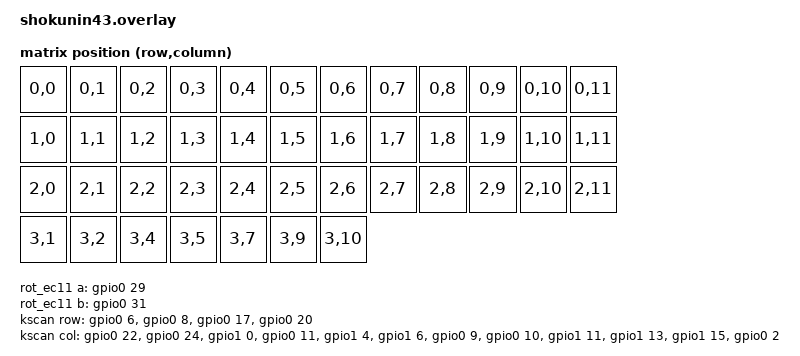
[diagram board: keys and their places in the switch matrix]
// This file was generated from a template. Edit it to match your keyboard.
// See https://zmk.dev/docs/development/hardware-integration/new-shield for more
// instructions.

#include <dt-bindings/zmk/matrix_transform.h>

#include "shokunin43-layouts.dtsi"

/ {
    chosen {
        zmk,physical-layout = &default_layout;
    };

	rot_ec11: encoder {
		compatible = "alps,ec11";
        a-gpios = <&gpio0 29 (GPIO_ACTIVE_HIGH | GPIO_PULL_UP)>;
        b-gpios = <&gpio0 31 (GPIO_ACTIVE_HIGH | GPIO_PULL_UP)>;
        steps = <80>;
	};

    sensors: sensors {
        compatible = "zmk,keymap-sensors";
        sensors = <&rot_ec11>;
        triggers-per-rotation = <20>;
        left {
            triggers-per-rotation = <20>;
        };
    };	

    kscan: kscan {
        // If the hardware does not use a switch matrix, change this to the
        // appropriate driver and update the properties below to match.
        // See https://zmk.dev/docs/config/kscan for supported key scan drivers.
        compatible = "zmk,kscan-gpio-matrix";
        // Set this to "col2row" or "row2col" to match the hardware. If using
        // "row2col", change the col-gpios to (GPIO_ACTIVE_HIGH | GPIO_PULL_DOWN)
        // and the row-gpios to GPIO_ACTIVE_HIGH.
        diode-direction = "col2row";
        wakeup-source;

        // Replace these comments with the GPIO pins in the matrix.
        // See https://zmk.dev/docs/development/hardware-integration/new-shield#shield-overlays
        col-gpios
            = <&gpio0 22 GPIO_ACTIVE_HIGH>
            , <&gpio0 24 GPIO_ACTIVE_HIGH>
            , <&gpio1 0 GPIO_ACTIVE_HIGH>
            , <&gpio0 11 GPIO_ACTIVE_HIGH>
            , <&gpio1 4 GPIO_ACTIVE_HIGH>
            , <&gpio1 6 GPIO_ACTIVE_HIGH>
            , <&gpio0 9 GPIO_ACTIVE_HIGH>
            , <&gpio0 10 GPIO_ACTIVE_HIGH>
            , <&gpio1 11 GPIO_ACTIVE_HIGH>
            , <&gpio1 13 GPIO_ACTIVE_HIGH>
            , <&gpio1 15 GPIO_ACTIVE_HIGH>
            , <&gpio0 2 GPIO_ACTIVE_HIGH>
            ;

        row-gpios
            = <&gpio0  6 (GPIO_ACTIVE_HIGH | GPIO_PULL_DOWN)>
            , <&gpio0  8 (GPIO_ACTIVE_HIGH | GPIO_PULL_DOWN)>
            , <&gpio0 17 (GPIO_ACTIVE_HIGH | GPIO_PULL_DOWN)>
            , <&gpio0 20 (GPIO_ACTIVE_HIGH | GPIO_PULL_DOWN)>
            ;
    };

    default_transform: default_transform {
        // See https://zmk.dev/docs/development/hardware-integration/new-shield#matrix-transform
        // for how to configure this
        compatible = "zmk,matrix-transform";
        columns = <12>;
        rows = <4>;

        map = <
            RC(0, 0) RC(0, 1) RC(0, 2) RC(0, 3) RC(0, 4) RC(0, 5) RC(0, 6) RC(0, 7) RC(0, 8) RC(0, 9) RC(0, 10) RC(0, 11) 

            RC(1, 0) RC(1, 1) RC(1, 2) RC(1, 3) RC(1, 4) RC(1, 5) RC(1, 6) RC(1, 7) RC(1, 8) RC(1, 9) RC(1, 10) RC(1, 11) 

            RC(2, 0) RC(2, 1) RC(2, 2) RC(2, 3) RC(2, 4) RC(2, 5) RC(2, 6) RC(2, 7) RC(2, 8) RC(2, 9) RC(2, 10) RC(2, 11) 

            RC(3, 1) RC(3, 2) RC(3, 4) RC(3, 5) RC(3, 7) RC(3, 9) RC(3, 10)
        >;
    };

};
